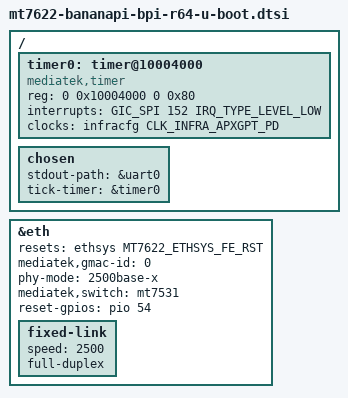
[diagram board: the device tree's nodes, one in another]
// SPDX-License-Identifier: GPL-2.0
/*
 * Copyright (c) 2019 MediaTek Inc.
 * Author: Frank Wunderlich <frank-w@public-files.de>
 */

/ {
	//mt7622
	timer0: timer@10004000 {
		compatible = "mediatek,timer";
		reg = <0 0x10004000 0 0x80>;
		interrupts = <GIC_SPI 152 IRQ_TYPE_LEVEL_LOW>;
		clocks = <&infracfg CLK_INFRA_APXGPT_PD>;
		clock-names = "system-clk";
	};
	//r64
	chosen {
		stdout-path = &uart0;
		tick-timer = &timer0;
	};
};

&eth {
	//mt7622
	//resets = <&ethsys ETHSYS_FE_RST>; //original mt7622.dtsi, wonder why it compiles :p
	resets = <&ethsys MT7622_ETHSYS_FE_RST>; //defined in mt7622-reset.h
	reset-names = "fe";
	//r64
	status = "okay";
	mediatek,gmac-id = <0>;
	phy-mode = "2500base-x";
	mediatek,switch = "mt7531";
	reset-gpios = <&pio 54 GPIO_ACTIVE_HIGH>;

	fixed-link {
		speed = <2500>;
		full-duplex;
	};
};
